# CSI_TX_IF_V2_1_COMMON_0_TX_SHIM_VBUSP_MMR_CSI2TXIF_V2 register map
Vendor: Texas Instruments
Peripheral module from a debugger description file (folder J721S2).
Registers are 32-bit, read-write, reset 0x0 unless marked. A register's access mark holds for its fields unless they carry their own. Offsets are as the file gives them; lines under a group give offsets from that group; [hi:lo] are bit positions; {n}, {i} and the like mark numbered series; 'fields as' and 'values as' point back to an identical list; <NAME> marks a mode.

## CSI_TX_IF_V2_1_COMMON_0_TX_SHIM_VBUSP_MMR_CSI2TXIF_V2
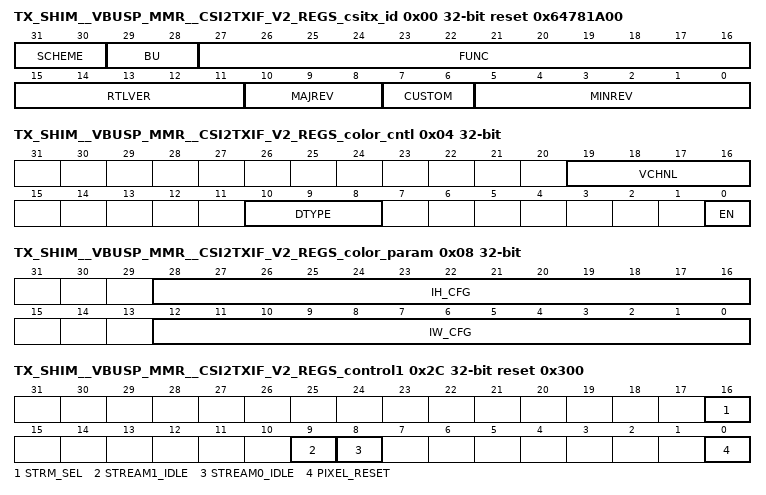
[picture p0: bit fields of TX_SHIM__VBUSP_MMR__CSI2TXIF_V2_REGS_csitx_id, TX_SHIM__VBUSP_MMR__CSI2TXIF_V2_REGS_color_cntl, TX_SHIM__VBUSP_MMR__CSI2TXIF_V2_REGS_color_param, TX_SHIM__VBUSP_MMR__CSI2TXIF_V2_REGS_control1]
0x00 TX_SHIM__VBUSP_MMR__CSI2TXIF_V2_REGS_csitx_id ro reset 0x64781A00
  [31:30] SCHEME
  [29:28] BU
  [27:16] FUNC — function
  [15:11] RTLVER — rtl version
  [10:8] MAJREV — major revision
  [7:6] CUSTOM — custom revision
  [5:0] MINREV — min revision
0x04 TX_SHIM__VBUSP_MMR__CSI2TXIF_V2_REGS_color_cntl
  [19:16] VCHNL — color bar virtual channel
  [10:8] DTYPE — color bar data type, data sel
  [0] EN — 1: enable
0x08 TX_SHIM__VBUSP_MMR__CSI2TXIF_V2_REGS_color_param
  [28:16] IH_CFG — input height in units of pixels minus 1.
  [12:0] IW_CFG — input width in units of pixels minus 1.
0x0C TX_SHIM__VBUSP_MMR__CSI2TXIF_V2_REGS_color_start_delay
  [31:0] LINE_DELAY — delay in terms of main clock cycles before sending first line after enabling.
0x20 TX_SHIM__VBUSP_MMR__CSI2TXIF_V2_REGS_color_line_delay
  [31:0] LINE_DELAY — delay in terms of main clock cycles from line start to next line start
0x24 TX_SHIM__VBUSP_MMR__CSI2TXIF_V2_REGS_color_frame_delay
  [31:0] FRAME_DELAY — delay in terms of main clock cycles from last line start to start of next frame
0x2C TX_SHIM__VBUSP_MMR__CSI2TXIF_V2_REGS_control1 access per field reset 0x300
  [16] STRM_SEL rw — select to switch dma versus retransmit interface mux, 0=dma, 1=retransmit
  [9] STREAM1_IDLE ro — indicates if stream interface is idle(1) or not(0)
  [8] STREAM0_IDLE ro — indicates if stream interface is idle(1) or not(0)
  [0] PIXEL_RESET rw — reset for the pixeal interface. 0=reset, 1 not in reset. this should be asserted till after you program the csi controller configuration registers
0x40 TX_SHIM__VBUSP_MMR__CSI2TXIF_V2_REGS_f2f_delay
  [31:0] DELAY — counter value delay of last line start of frame to first line of next frame
